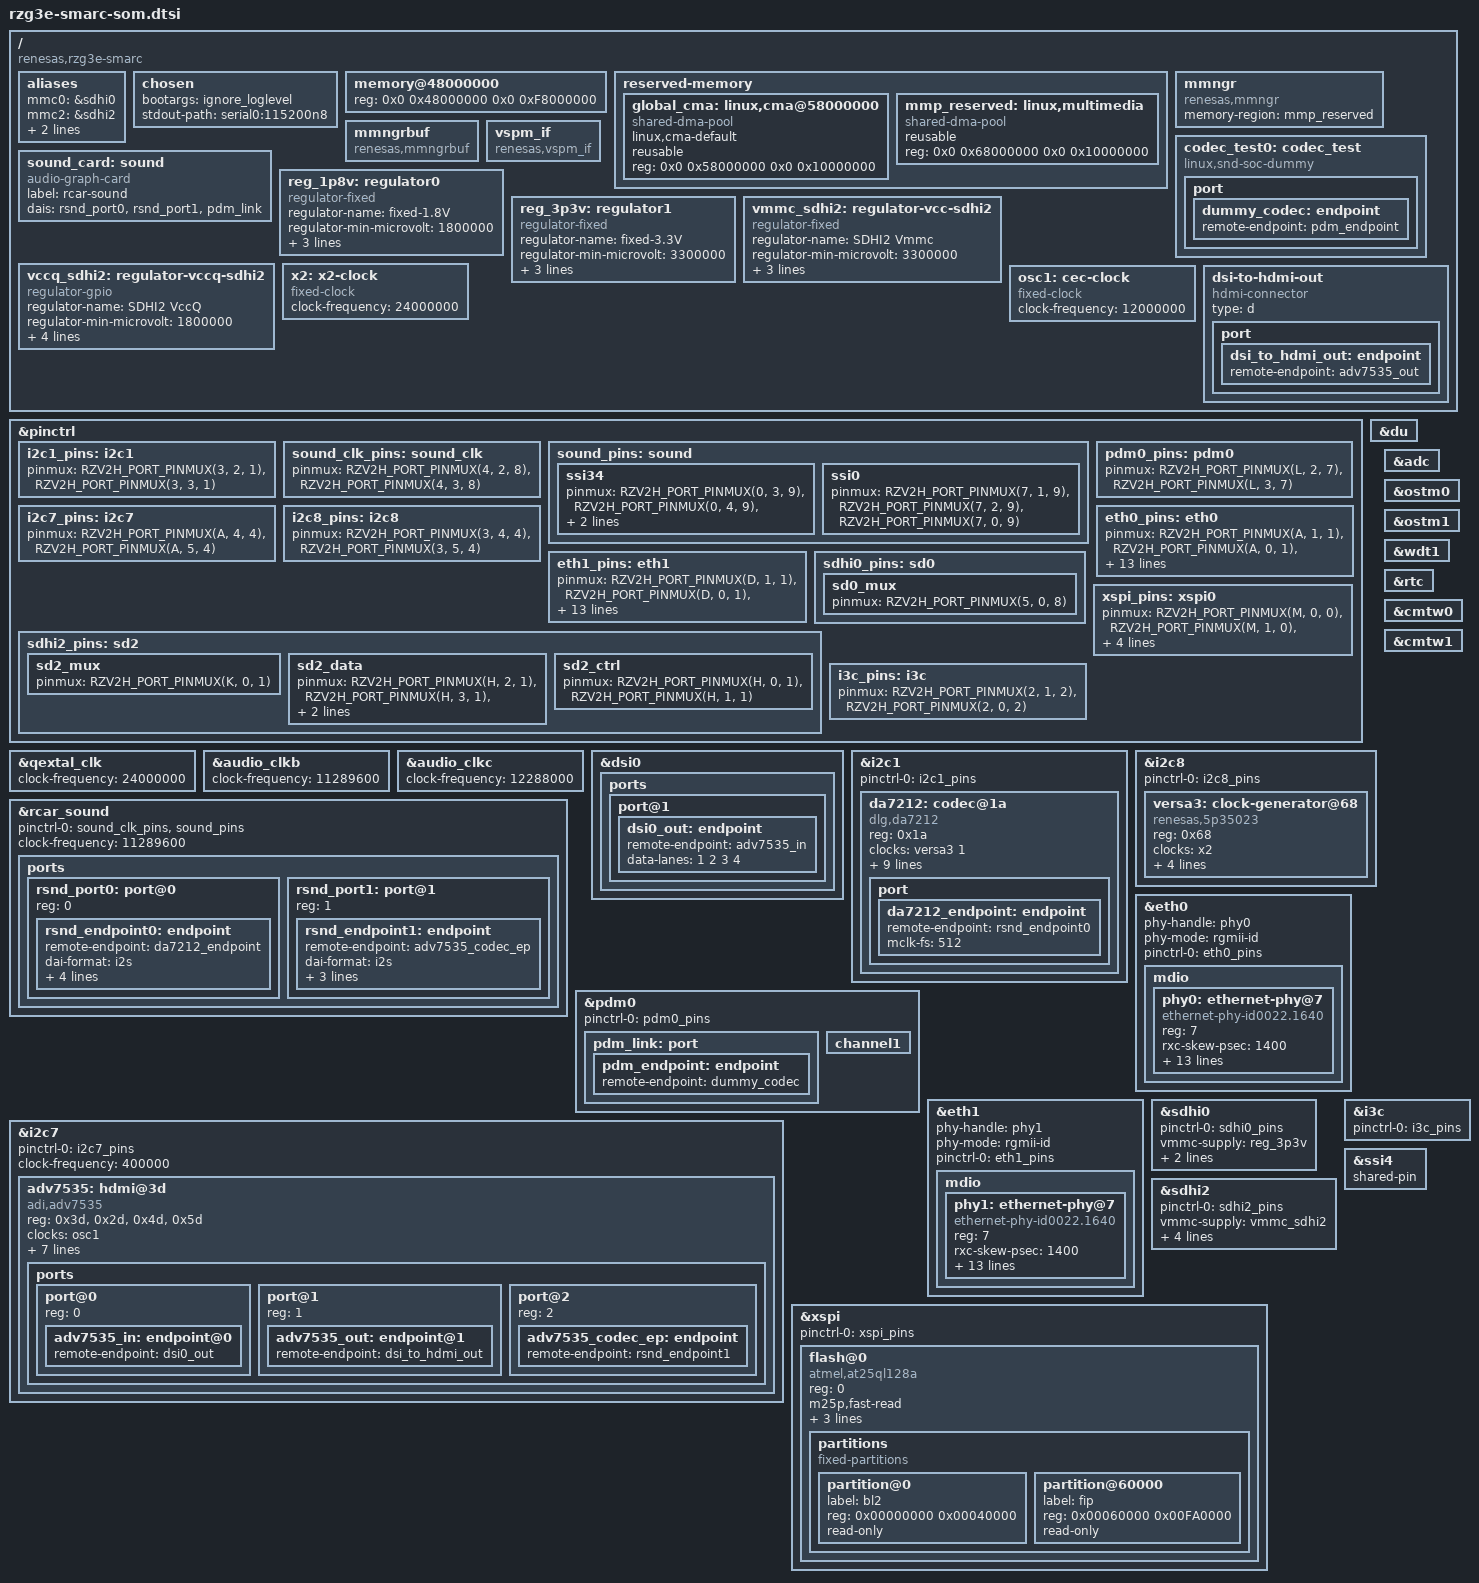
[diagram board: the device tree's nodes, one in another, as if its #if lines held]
// SPDX-License-Identifier: (GPL-2.0-only OR BSD-2-Clause)
/*
 * Device Tree Source for the R9A09G047E54 SMARC Carrier-II's SoM board.
 *
 * Copyright (C) 2024 Renesas Electronics Corp.
 */

#include <dt-bindings/gpio/gpio.h>
#include <dt-bindings/pinctrl/rzv2h-pinctrl.h>
#include <dt-bindings/interrupt-controller/irqc-rzg2l.h>

/*
 * SW #4 states:
 *
 * Please change the corresponding selection to below Macros:
 *
 * SW_LCD_EN:
 *	0 - Connects to Carrier for CAN, GPIO, Serial, SPI (default)
 *	1 - Connects to Parallel display
 * SW_SD0_DEV_SEL:
 *      0 - SD0 is connected to eMMC (default)
 *      1 - SD0 is connected to uSD0 card
 * SW_SER2_EN:
 *	0 - Connects to Carrier SER2(SCI2) (default)
 *	1 - Connects to Module DSI connector(GPIO)
 * SW_HDMI_EN when RZG3E_SMARC_MIPI_DSI_ENABLE is set:
 *	0 - MIPI DSI is connected to Carrier HDMI (default)
 *	1 - MIPI DSI is connected to Module DSI connector
 *
 * SW #5 states:
 *
 * Please change the corresponding selection to below Macros:
 *
 * SW_PDM_EN:
 *	0 - Connects to Carrier for CAN1 (default)
 *	1 - Connects to MEMS Microphone
 */

/*
 * SSI-DA7212
 *
 * These commands are required when Playback/Capture
 *
 *	amixer -q cset name='Aux Switch' on
 *	amixer -q cset name='Mixin Left Aux Left Switch' on
 *	amixer -q cset name='Mixin Right Aux Right Switch' on
 *	amixer -q cset name='ADC Switch' on
 *	amixer -q cset name='Mixout Right Mixin Right Switch' off
 *	amixer -q cset name='Mixout Left Mixin Left Switch' off
 *	amixer -q cset name='Headphone Volume' 70%
 *	amixer -q cset name='Headphone Switch' on
 *	amixer -q cset name='Mixout Left DAC Left Switch' on
 *	amixer -q cset name='Mixout Right DAC Right Switch' on
 *	amixer -q cset name='DAC Left Source MUX' 'DAI Input Left'
 *	amixer -q cset name='DAC Right Source MUX' 'DAI Input Right'
 *	amixer -q sset 'Mic 1 Amp Source MUX' 'MIC_P'
 *	amixer -q sset 'Mic 2 Amp Source MUX' 'MIC_P'
 *	amixer -q sset 'Mixin Left Mic 1' on
 *	amixer -q sset 'Mixin Right Mic 2' on
 *	amixer -q sset 'Mic 1' 90% on
 *	amixer -q sset 'Mic 2' 90% on
 *	amixer -q sset 'Lineout' 80% on
 *	amixer -q set "Headphone" 100% on
 *
 * When Capture, use this command to amplify sound
 *	amixer set 'DVC In',0 10%
 */

/ {
	compatible = "renesas,rzg3e-smarc", "renesas,r9a09g047e57", "renesas,r9a09g047";

	aliases {
		mmc0 = &sdhi0;
		mmc2 = &sdhi2;
		ethernet0 = &eth0;
		ethernet1 = &eth1;
	};

	chosen {
		bootargs = "ignore_loglevel";
		stdout-path = "serial0:115200n8";
	};

	memory@48000000 {
		device_type = "memory";
		/* first 128MB is reserved for secure area. */
		reg = <0x0 0x48000000 0x0 0xF8000000>;
	};

	reserved-memory {
		#address-cells = <2>;
		#size-cells = <2>;
		ranges;

		global_cma: linux,cma@58000000 {
			compatible = "shared-dma-pool";
			linux,cma-default;
			reusable;
			reg = <0x0 0x58000000 0x0 0x10000000>;
		};

		mmp_reserved: linux,multimedia {
			compatible = "shared-dma-pool";
			reusable;
			reg = <0x0 0x68000000 0x0 0x10000000>;
		};
	};

	mmngr {
		compatible = "renesas,mmngr";
		memory-region = <&mmp_reserved>;
	};

	mmngrbuf {
		compatible = "renesas,mmngrbuf";
	};

	vspm_if {
		compatible = "renesas,vspm_if";
	};

#if (SW_PDM_EN)
	codec_test0: codec_test {
		compatible = "linux,snd-soc-dummy";
		#sound-dai-cells = <0>;
	port {
		dummy_codec: endpoint {
			remote-endpoint = <&pdm_endpoint>;
			};
		};
	};
#endif

	sound_card: sound {
		compatible = "audio-graph-card";

		label = "rcar-sound";
#if (!I2C1_GPT_SEL)
		dais = <&rsnd_port0	/* DA7211 */
#if (!SW_LCD_EN)
			&rsnd_port1	/* HDMI0  */
#endif
#if (SW_PDM_EN)
			&pdm_link
#endif
			>;
#else
		dais = <
#if (!SW_LCD_EN)
			&rsnd_port0	/* HDMI0 */
#endif
#if (SW_PDM_EN)
			&pdm_link
#endif
			>;
#endif
	};

	reg_1p8v: regulator0 {
		compatible = "regulator-fixed";

		regulator-name = "fixed-1.8V";
		regulator-min-microvolt = <1800000>;
		regulator-max-microvolt = <1800000>;
		regulator-boot-on;
		regulator-always-on;
	};

	reg_3p3v: regulator1 {
		compatible = "regulator-fixed";

		regulator-name = "fixed-3.3V";
		regulator-min-microvolt = <3300000>;
		regulator-max-microvolt = <3300000>;
		regulator-boot-on;
		regulator-always-on;
	};

	vmmc_sdhi2: regulator-vcc-sdhi2 {
		compatible = "regulator-fixed";

		regulator-name = "SDHI2 Vmmc";
		regulator-min-microvolt = <3300000>;
		regulator-max-microvolt = <3300000>;

		gpios = <&pinctrl RZV2H_GPIO(K, 2) GPIO_ACTIVE_HIGH>;
		enable-active-high;
	};

	vccq_sdhi2: regulator-vccq-sdhi2 {
		compatible = "regulator-gpio";

		regulator-name = "SDHI2 VccQ";
		regulator-min-microvolt = <1800000>;
		regulator-max-microvolt = <3300000>;

		gpios = <&pinctrl RZV2H_GPIO(K, 1) GPIO_ACTIVE_HIGH>;

		gpios-states = <0>;
		states = <3300000 0 1800000 1>;
	};

	x2: x2-clock {
		compatible = "fixed-clock";
		#clock-cells = <0>;
		clock-frequency = <24000000>;
	};

	osc1: cec-clock {
		compatible = "fixed-clock";
		#clock-cells = <0>;
		clock-frequency = <12000000>;
	};

#if (RZG3E_SMARC_MIPI_DSI_ENABLE)
	dsi-to-hdmi-out {
		compatible = "hdmi-connector";
		type = "d";

		port {
			dsi_to_hdmi_out: endpoint {
				remote-endpoint = <&adv7535_out>;
			};
		};
	};
#endif
};

&pinctrl {

#if (!I2C1_GPT_SEL)
	i2c1_pins: i2c1 {
		pinmux = <RZV2H_PORT_PINMUX(3, 2, 1)>, /* SCL */
			 <RZV2H_PORT_PINMUX(3, 3, 1)>; /* SDA */
	};

#endif
	sound_clk_pins: sound_clk {
		pinmux = <RZV2H_PORT_PINMUX(4, 2, 8)>, /* AUDIO_CLKB */
			 <RZV2H_PORT_PINMUX(4, 3, 8)>; /* AUDIO_CLKC */
	};

	sound_pins: sound {
#if (!I2C1_GPT_SEL)
		ssi34 {
			pinmux = <RZV2H_PORT_PINMUX(0, 3, 9)>, /* SSI3_SCK */
				 <RZV2H_PORT_PINMUX(0, 4, 9)>, /* SSI3_WS */
				 <RZV2H_PORT_PINMUX(0, 2, 9)>, /* SSI3_SDATA */
				 <RZV2H_PORT_PINMUX(0, 5, 9)>; /* SSI4_SDATA */
		};
#endif
#if (!SW_LCD_EN)
		ssi0 {
			pinmux = <RZV2H_PORT_PINMUX(7, 1, 9)>, /* SSI0_SCK */
				 <RZV2H_PORT_PINMUX(7, 2, 9)>, /* SSI0_WS */
				 <RZV2H_PORT_PINMUX(7, 0, 9)>; /* SSI0_SDATA */
		};
#endif
	};
#if (SW_PDM_EN)
	pdm0_pins: pdm0 {
		pinmux = <RZV2H_PORT_PINMUX(L, 2, 7)>, /* PDMCLK01 */
			 <RZV2H_PORT_PINMUX(L, 3, 7)>; /* PDMDAT01 */
	};

#endif

	i2c7_pins: i2c7 {
		pinmux = <RZV2H_PORT_PINMUX(A, 4, 4)>, /* SCL */
			 <RZV2H_PORT_PINMUX(A, 5, 4)>; /* SDA */
	};

	i2c8_pins: i2c8 {
		pinmux = <RZV2H_PORT_PINMUX(3, 4, 4)>, /* SCL */
			 <RZV2H_PORT_PINMUX(3, 5, 4)>; /* SDA */
	};

	eth0_pins: eth0 {
		pinmux = <RZV2H_PORT_PINMUX(A, 1, 1)>, /* MDC */
			 <RZV2H_PORT_PINMUX(A, 0, 1)>, /* MDIO */
			 <RZV2H_PORT_PINMUX(C, 2, 15)>, /* PHY_INTR */
			 <RZV2H_PORT_PINMUX(C, 1, 1)>, /* RXD3 */
			 <RZV2H_PORT_PINMUX(C, 0, 1)>, /* RXD2 */
			 <RZV2H_PORT_PINMUX(B, 7, 1)>, /* RXD1 */
			 <RZV2H_PORT_PINMUX(B, 6, 1)>, /* RXD0 */
			 <RZV2H_PORT_PINMUX(B, 0, 1)>, /* RXC */
			 <RZV2H_PORT_PINMUX(A, 2, 1)>, /* RX_CTL */
			 <RZV2H_PORT_PINMUX(B, 5, 1)>, /* TXD3 */
			 <RZV2H_PORT_PINMUX(B, 4, 1)>, /* TXD2 */
			 <RZV2H_PORT_PINMUX(B, 3, 1)>, /* TXD1 */
			 <RZV2H_PORT_PINMUX(B, 2, 1)>, /* TXD0 */
			 <RZV2H_PORT_PINMUX(B, 1, 1)>, /* TXC */
			 <RZV2H_PORT_PINMUX(A, 3, 1)>; /* TX_CTL */
	};

	eth1_pins: eth1 {
		pinmux = <RZV2H_PORT_PINMUX(D, 1, 1)>, /* MDC */
			 <RZV2H_PORT_PINMUX(D, 0, 1)>, /* MDIO */
			 <RZV2H_PORT_PINMUX(F, 2, 15)>, /* PHY_INTR */
			 <RZV2H_PORT_PINMUX(F, 1, 1)>, /* RXD3 */
			 <RZV2H_PORT_PINMUX(F, 0, 1)>, /* RXD2 */
			 <RZV2H_PORT_PINMUX(E, 7, 1)>, /* RXD1 */
			 <RZV2H_PORT_PINMUX(E, 6, 1)>, /* RXD0 */
			 <RZV2H_PORT_PINMUX(E, 0, 1)>, /* RXC */
			 <RZV2H_PORT_PINMUX(D, 2, 1)>, /* RX_CTL */
			 <RZV2H_PORT_PINMUX(E, 5, 1)>, /* TXD3 */
			 <RZV2H_PORT_PINMUX(E, 4, 1)>, /* TXD2 */
			 <RZV2H_PORT_PINMUX(E, 3, 1)>, /* TXD1 */
			 <RZV2H_PORT_PINMUX(E, 2, 1)>, /* TXD0 */
			 <RZV2H_PORT_PINMUX(E, 1, 1)>, /* TXC */
			 <RZV2H_PORT_PINMUX(D, 3, 1)>; /* TX_CTL */
	};

#if (SW_SD0_DEV_SEL)
	/* Support pinctrl for SD function of SDHI0 */
	sdhi0_pins: sd0 {
		sd0_mux {
			pinmux = <RZV2H_PORT_PINMUX(5, 0, 8)>; /* SD0_CD */
		};
	};
#endif

	sdhi2_pins: sd2 {
		sd2_mux {
			pinmux = <RZV2H_PORT_PINMUX(K, 0, 1)>; /* QSD2_CD */
		};

		sd2_data {
			pinmux = <RZV2H_PORT_PINMUX(H, 2, 1)>, /* QSD2_DAT0 */
				 <RZV2H_PORT_PINMUX(H, 3, 1)>, /* QSD2_DAT1 */
				 <RZV2H_PORT_PINMUX(H, 4, 1)>, /* QSD2_DAT2 */
				 <RZV2H_PORT_PINMUX(H, 5, 1)>; /* QSD2_DAT3 */
		};

		sd2_ctrl {
			pinmux = <RZV2H_PORT_PINMUX(H, 0, 1)>, /* QSD2_CLK */
				 <RZV2H_PORT_PINMUX(H, 1, 1)>; /* QSD2_CMD */
		};
	};

	xspi_pins: xspi0 {
		pinmux = <RZV2H_PORT_PINMUX(M, 0, 0)>, /* XSPI0_IO0 */
			 <RZV2H_PORT_PINMUX(M, 1, 0)>, /* XSPI0_IO1 */
			 <RZV2H_PORT_PINMUX(M, 2, 0)>, /* XSPI0_IO2 */
			 <RZV2H_PORT_PINMUX(M, 3, 0)>, /* XSPI0_IO3 */
			 <RZV2H_PORT_PINMUX(L, 0, 0)>, /* XSPI0_CKP */
			 <RZV2H_PORT_PINMUX(L, 1, 0)>; /* XSPI0_CS0 */
	};

	i3c_pins: i3c {
		pinmux = <RZV2H_PORT_PINMUX(2, 1, 2)>, /* I3C_SDA */
			 <RZV2H_PORT_PINMUX(2, 0, 2)>; /* I3C_SCL */
	};
};

&qextal_clk {
	clock-frequency = <24000000>;
};

&audio_clkb {
	clock-frequency = <11289600>;
};

&audio_clkc {
	clock-frequency = <12288000>;
};

&du {
	status = "okay";
};

#if (RZG3E_SMARC_MIPI_DSI_ENABLE)
&dsi0 {
	status = "okay";

	ports {
		port@1 {
			dsi0_out: endpoint {
#if (!SW_HDMI_EN)
				remote-endpoint = <&adv7535_in>;
				data-lanes = <1 2 3 4>;
#endif
			};
		};
	};
};
#endif

#if (!I2C1_GPT_SEL)
&i2c1 {
	pinctrl-0 = <&i2c1_pins>;
	pinctrl-names = "default";

	status = "okay";

	da7212: codec@1a {
		compatible = "dlg,da7212";
		#sound-dai-cells = <0>;
		#address-cells = <1>;
		#size-cells = <0>;
		reg = <0x1a>;

		clocks = <&versa3 1>;
		clock-names = "mclk";

		dlg,micbias1-lvl = <2500>;
		dlg,micbias2-lvl = <2500>;
		dlg,dmic-data-sel = "lrise_rfall";
		dlg,dmic-samplephase = "between_clkedge";
		dlg,dmic-clkrate = <3000000>;

		VDDA-supply = <&reg_1p8v>;
		VDDSP-supply = <&reg_3p3v>;
		VDDMIC-supply = <&reg_3p3v>;
		VDDIO-supply = <&reg_1p8v>;

		port {
			da7212_endpoint: endpoint {
				remote-endpoint = <&rsnd_endpoint0>;
				mclk-fs = <512>;
			};
		};
	};
};
#endif

&rcar_sound {
	pinctrl-0 = <&sound_clk_pins &sound_pins>;
	pinctrl-names = "default";

	status = "okay";

	/* audio_clkout */
	#clock-cells = <0>;
	clock-frequency = <11289600>;

	/* Multi DAI */
	#sound-dai-cells = <1>;

	ports {
		#address-cells = <1>;
		#size-cells = <0>;
#if (!I2C1_GPT_SEL)
		rsnd_port0: port@0 {
			reg = <0>;
			rsnd_endpoint0: endpoint {
				remote-endpoint = <&da7212_endpoint>;

				dai-format = "i2s";
				bitclock-master = <&rsnd_endpoint0>;
				frame-master = <&rsnd_endpoint0>;

				playback = <&ssi3>;
				capture = <&ssi4>, <&src0>, <&dvc0>;
			};
		};

#if (!SW_LCD_EN)
		rsnd_port1: port@1 {
			reg = <1>;
			rsnd_endpoint1: endpoint {
#if ((RZG3E_SMARC_MIPI_DSI_ENABLE) && (!SW_HDMI_EN))
				remote-endpoint = <&adv7535_codec_ep>;
#endif

				dai-format = "i2s";
				bitclock-master = <&rsnd_endpoint1>;
				frame-master = <&rsnd_endpoint1>;

				playback = <&ssi0>;
			};
		};
#endif
#else
#if (!SW_LCD_EN)
		rsnd_port0: port@0 {
			reg = <0>;
			rsnd_endpoint0: endpoint {
#if ((RZG3E_SMARC_MIPI_DSI_ENABLE) && (!SW_HDMI_EN))
				remote-endpoint = <&adv7535_codec_ep>;
#endif

				dai-format = "i2s";
				bitclock-master = <&rsnd_endpoint0>;
				frame-master = <&rsnd_endpoint0>;

				playback = <&ssi0>;
			};
		};
#endif
#endif
	};
};

#if (SW_PDM_EN)
&pdm0 {
	pinctrl-0 = <&pdm0_pins>;
	pinctrl-names = "default";
	status = "okay";

	pdm_link: port {
		pdm_endpoint: endpoint {
			remote-endpoint = <&dummy_codec>;
		};
	};

	channel1 {
		status = "okay";
	};
};
#endif

&i2c7 {
	pinctrl-0 = <&i2c7_pins>;
	pinctrl-names = "default";
	clock-frequency = <400000>;

	status = "okay";

#if ((RZG3E_SMARC_MIPI_DSI_ENABLE) && (!SW_HDMI_EN))
	adv7535: hdmi@3d {

		compatible = "adi,adv7535";
		reg = <0x3d>, <0x2d>, <0x4d>, <0x5d>;
		reg-names = "main", "cec", "edid", "packet";

		clocks = <&osc1>;
		clock-names = "cec";
		avdd-supply = <&reg_1p8v>;
		dvdd-supply = <&reg_1p8v>;
		pvdd-supply = <&reg_1p8v>;
		a2vdd-supply = <&reg_1p8v>;
		v3p3-supply = <&reg_3p3v>;
		v1p2-supply = <&reg_1p8v>;

		adi,dsi-lanes = <4>;

		ports {
			#address-cells = <1>;
			#size-cells = <0>;

			port@0 {
				reg = <0>;
				adv7535_in: endpoint@0 {
					remote-endpoint = <&dsi0_out>;
				};
			};

			port@1 {
				reg = <1>;
				adv7535_out: endpoint@1 {
					remote-endpoint = <&dsi_to_hdmi_out>;
				};
			};

#if (!SW_LCD_EN)

			port@2 {
				reg = <2>;
				adv7535_codec_ep: endpoint {
#if (!I2C1_GPT_SEL)
					remote-endpoint = <&rsnd_endpoint1>;
#else
					remote-endpoint = <&rsnd_endpoint0>;
#endif
				};
			};
#endif

		};
	};
#endif
};

&i2c8 {
	pinctrl-0 = <&i2c8_pins>;
	pinctrl-names = "default";
	status = "okay";

	versa3: clock-generator@68 {
		compatible = "renesas,5p35023";
		reg = <0x68>;
		#clock-cells = <1>;
		clocks = <&x2>;

		assigned-clocks = <&versa3 0>, <&versa3 1>,
				  <&versa3 2>, <&versa3 3>,
				  <&versa3 4>, <&versa3 5>;
		assigned-clock-rates = <24000000>, <12288000>,
				       <11289600>, <12288000>,
				       <25000000>, <25000000>;
	};
};

&eth0 {
	phy-handle = <&phy0>;
	phy-mode = "rgmii-id";

	pinctrl-0 = <&eth0_pins>;
	pinctrl-names = "default";
	status = "okay";

	mdio {
		#address-cells = <1>;
		#size-cells = <0>;
		phy0: ethernet-phy@7 {
			compatible = "ethernet-phy-id0022.1640",
					"ethernet-phy-ieee802.3-c22";
			reg = <7>;
			rxc-skew-psec = <1400>;
			txc-skew-psec = <1400>;
			rxdv-skew-psec = <0>;
			txdv-skew-psec = <0>;
			rxd0-skew-psec = <0>;
			rxd1-skew-psec = <0>;
			rxd2-skew-psec = <0>;
			rxd3-skew-psec = <0>;
			txd0-skew-psec = <0>;
			txd1-skew-psec = <0>;
			txd2-skew-psec = <0>;
			txd3-skew-psec = <0>;

			interrupt-parent = <&icu>;
			interrupts = <RZG2L_IRQ2 IRQ_TYPE_LEVEL_LOW>;
		};
	};
};

&eth1 {
	phy-handle = <&phy1>;
	phy-mode = "rgmii-id";

	pinctrl-0 = <&eth1_pins>;
	pinctrl-names = "default";
	status = "okay";

	mdio {
		#address-cells = <1>;
		#size-cells = <0>;
		phy1: ethernet-phy@7 {
			compatible = "ethernet-phy-id0022.1640",
					"ethernet-phy-ieee802.3-c22";
			reg = <7>;
			rxc-skew-psec = <1400>;
			txc-skew-psec = <1400>;
			rxdv-skew-psec = <0>;
			txdv-skew-psec = <0>;
			rxd0-skew-psec = <0>;
			rxd1-skew-psec = <0>;
			rxd2-skew-psec = <0>;
			rxd3-skew-psec = <0>;
			txd0-skew-psec = <0>;
			txd1-skew-psec = <0>;
			txd2-skew-psec = <0>;
			txd3-skew-psec = <0>;

			interrupt-parent = <&icu>;
			interrupts = <RZG2L_IRQ15 IRQ_TYPE_LEVEL_LOW>;
		};
	};
};

#if (SW_SD0_DEV_SEL)
/* SD0 slot */
&sdhi0 {
	pinctrl-0 = <&sdhi0_pins>;
	pinctrl-names = "default";

	vmmc-supply = <&reg_3p3v>;
	vqmmc-supply = <&reg_1p8v>;

	bus-width = <4>;
	status = "okay";
};
#else
/* eMMC */
&sdhi0 {
	vmmc-supply = <&reg_3p3v>;
	vqmmc-supply = <&reg_1p8v>;
	bus-width = <8>;
	mmc-hs200-1_8v;
	non-removable;
	fixed-emmc-driver-type = <1>;
	status = "okay";
};
#endif

&sdhi2 {
	pinctrl-0 = <&sdhi2_pins>;
	pinctrl-names = "default";

	vmmc-supply = <&vmmc_sdhi2>;
	vqmmc-supply = <&vccq_sdhi2>;
	bus-width = <4>;
	sd-uhs-sdr50;
	sd-uhs-sdr104;
	status = "okay";
};

&adc {
       status = "okay";
};

&ostm0 {
	status = "okay";
};

&ostm1 {
	status = "okay";
};

&xspi {
	pinctrl-0 = <&xspi_pins>;
	pinctrl-names = "default";
	status = "okay";

	flash@0 {
		compatible = "atmel,at25ql128a", "jedec,spi-nor";
		reg = <0>;
		m25p,fast-read;
		spi-max-frequency = <50000000>;
		spi-tx-bus-width = <1>;
		spi-rx-bus-width = <1>;

		partitions {
			compatible = "fixed-partitions";
			#address-cells = <1>;
			#size-cells = <1>;

			partition@0 {
				label = "bl2";
				reg = <0x00000000 0x00040000>;
				read-only;
			};

			partition@60000 {
				label = "fip";
				reg = <0x00060000 0x00FA0000>;
				read-only;
			};
		};
	};
};

&wdt1 {
	status = "okay";
};

&rtc {
	status = "okay";
};

&cmtw0 {
	status = "okay";
};

&cmtw1 {
	status = "okay";
};

&i3c {
	pinctrl-0 = <&i3c_pins>;
	pinctrl-names = "default";
	status = "okay";
};

#if (!I2C1_GPT_SEL)

&ssi4 {
	shared-pin;
};

#endif
